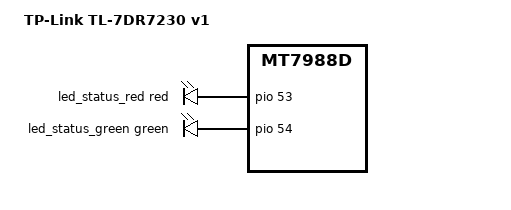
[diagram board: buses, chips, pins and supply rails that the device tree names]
// SPDX-License-Identifier: GPL-2.0-or-later OR MIT

/dts-v1/;
#include "mt7988d-tplink-tl-7dr7230.dtsi"

/ {
	model = "TP-Link TL-7DR7230 v1";
	compatible = "tplink,tl-7dr7230-v1", "mediatek,mt7988d";

	aliases {
		led-boot = &led_status_green;
		led-failsafe = &led_status_red;
		led-running = &led_status_green;
		led-upgrade = &led_status_red;
	};

	leds {
		compatible = "gpio-leds";

		led_status_red: status-red {
			function = LED_FUNCTION_STATUS;
			color = <LED_COLOR_ID_RED>;
			gpios = <&pio 53 GPIO_ACTIVE_HIGH>;
		};

		led_status_green: status-green {
			function = LED_FUNCTION_STATUS;
			color = <LED_COLOR_ID_GREEN>;
			gpios = <&pio 54 GPIO_ACTIVE_HIGH>;
		};
	};
};
